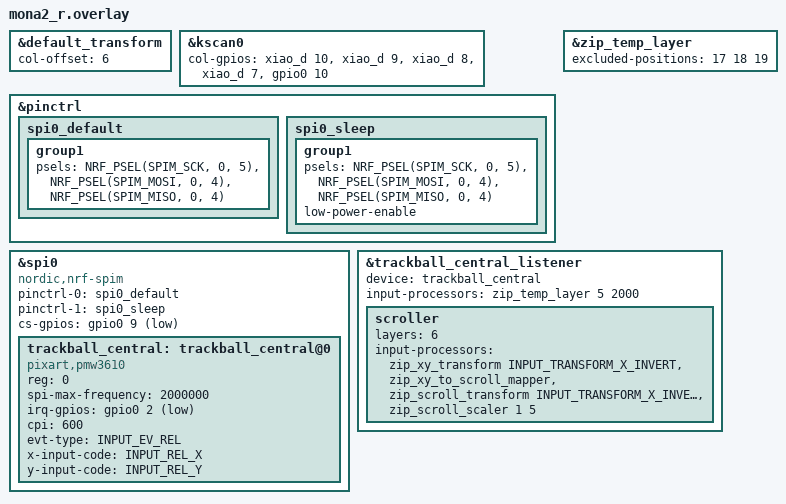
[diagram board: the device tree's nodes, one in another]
#include "mona2.dtsi"
#include <input/processors.dtsi>
#include <zephyr/dt-bindings/input/input-event-codes.h>

&default_transform {
    col-offset = <6>;
};

&kscan0 {
    col-gpios
        = <&xiao_d 10 GPIO_ACTIVE_HIGH>
        , <&xiao_d 9 GPIO_ACTIVE_HIGH> 
        , <&xiao_d 8 GPIO_ACTIVE_HIGH> 
        , <&xiao_d 7 GPIO_ACTIVE_HIGH> 
        , <&gpio0 10 GPIO_ACTIVE_HIGH>
        ;
};

&pinctrl {
    spi0_default: spi0_default {
        group1 {
            psels = <NRF_PSEL(SPIM_SCK, 0, 5)>,
                <NRF_PSEL(SPIM_MOSI, 0, 4)>,
                <NRF_PSEL(SPIM_MISO, 0, 4)>;
        };
    };

    spi0_sleep: spi0_sleep {
        group1 {
            psels = <NRF_PSEL(SPIM_SCK, 0, 5)>,
                <NRF_PSEL(SPIM_MOSI, 0, 4)>,
                <NRF_PSEL(SPIM_MISO, 0, 4)>;
            low-power-enable;
        };
    };
};

&spi0 {
    status = "okay";
    compatible = "nordic,nrf-spim";
    pinctrl-0 = <&spi0_default>;
    pinctrl-1 = <&spi0_sleep>;
    pinctrl-names = "default", "sleep";
    cs-gpios = <&gpio0 9 GPIO_ACTIVE_LOW>;

    trackball_central: trackball_central@0 {
        status = "okay";
        compatible = "pixart,pmw3610";
        reg = <0>;
        spi-max-frequency = <2000000>;
        irq-gpios = <&gpio0 2 (GPIO_ACTIVE_LOW | GPIO_PULL_UP)>;
        cpi = <600>;
        evt-type = <INPUT_EV_REL>;
        x-input-code = <INPUT_REL_X>;
        y-input-code = <INPUT_REL_Y>;
        
        /* AML（古いオートマウス機能）が有効にならないよう明示的に削除 */
        /delete-property/ automouse-layer;
    };
};

/* 画像から追加：一時レイヤーの設定 */
&zip_temp_layer {
    excluded-positions = <
        17 // J
        18 // K
        19 // L
    >;
};

/* リスナー設定の統合 */
&trackball_central_listener {
    status = "okay";
    device = <&trackball_central>;

    /* 1. トラボを動かした時に発動する設定 */
    /* 第1引数：移行先レイヤー(5)、第2引数：タイムアウト(2000ms=2秒) */
    input-processors = <&zip_temp_layer 5 2000>;

    /* 2. レイヤー6にいる時だけスクロールにする設定 */
    scroller {
        layers = <6>;
        input-processors = 
            <&zip_xy_transform INPUT_TRANSFORM_X_INVERT>,
            <&zip_xy_to_scroll_mapper>,
            <&zip_scroll_transform INPUT_TRANSFORM_X_INVERT>,
            <&zip_scroll_scaler 1 5>;
    };
};
